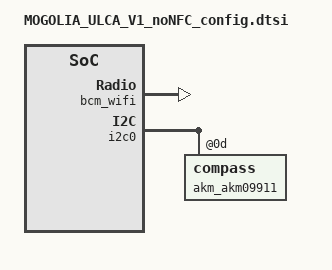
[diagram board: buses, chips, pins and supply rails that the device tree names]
/*
 * Hisilicon Ltd.
 *
 * A15x4 A7x4
 *
 * It is only a demo for hisilicon hi3630 board. You show change the
 * address of each node according to datasheet.
 */


/include/ "huawei-sensor.dtsi"
/include/ "fastboot.dtsi"
/include/ "MOGOLIA_TL_V1_config.dtsi"
/include/ "MOGOLIA_ULCA_V1_noNFC_pin.dtsi"

/ {
		hisi,boardid = <9 1 1 7>;
		hisi,boardname = "MOGOLIA_ULCA_V1_noNFC";
		hisi,modem_id = <0x3fb07000>;


	audio_hal_config {
		aud_para = "MOGOLIA_ULCA";
	};

	bcm_wifi {
		wifi_nvram_name = "/vendor/firmware/nvram4334_hw_mogolia_ulca.txt";
		wifi_fw_name = "/vendor/firmware/fw_bcm4334_hw_dualband.bin";
		wifi_fw_ap_name = "/vendor/firmware/fw_bcm4334_apsta_hw_dualband.bin";
		wifi_fw_test_name = "/vendor/firmware/fw_bcm4334_test_hw_apsta_dualband.bin";
		udp_board;
		ic_type= "bcm4334";
		status = "ok";
	};

	devcheck: devcheck {
		nfc = <0>;
	};
	amba{
    i2c0: i2c@FDF09000{
        akm_akm09911:compass@0d{
           softiron_parameter = <53 81 134 4 251 12 255 197 218 55 35 194 201 129 255 167 255 5 20 151 197 252 226 116 11 197 91>;
            };
	    };	
    };
};
